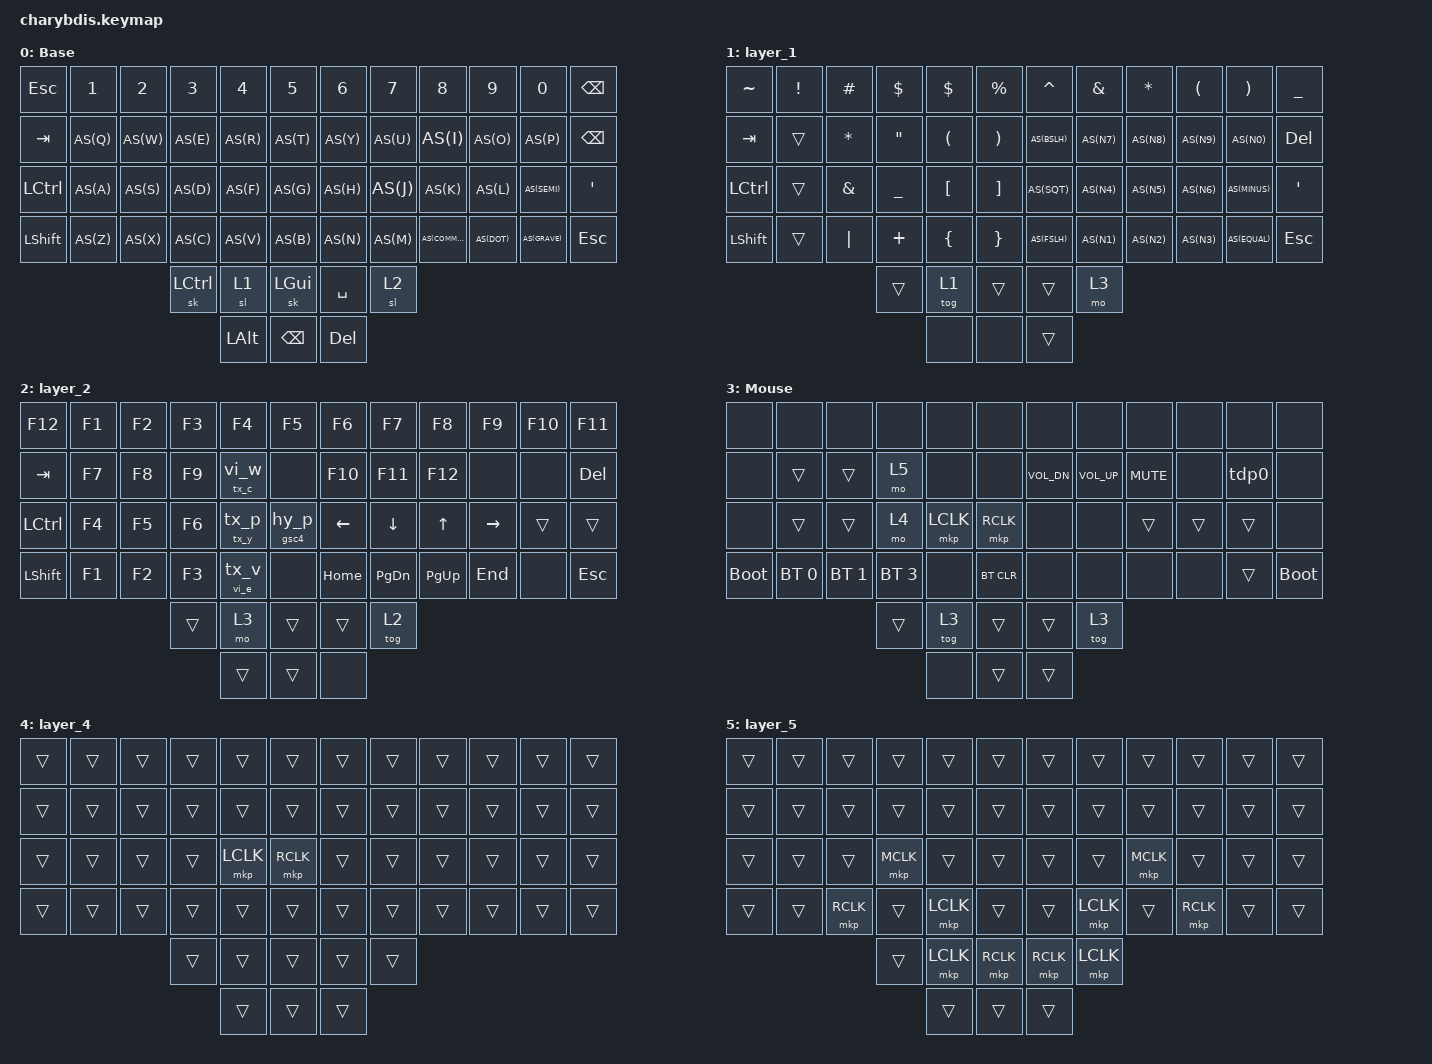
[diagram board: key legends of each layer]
#include <dt-bindings/zmk/mouse.h>
#include <behaviors.dtsi>
#include <dt-bindings/zmk/bt.h>
#include <dt-bindings/zmk/keys.h>

#define AS(keycode) &as LS(keycode) keycode     // Autoshift Macro

&tmv_fine {
    scale_factor = <3>;
};

&tmv_coarse {
    scale_mode = "multiplier";
    scale_factor = <3>;
};

&tsl {
    scale_factor = <8>;
};

/ {
    macros {
        vi_w: vi_w {
            label = "VIM_SAVE";
            compatible = "zmk,behavior-macro";
            #binding-cells = <0>;
            wait-ms = <40>;
            tap-ms = <40>;
            bindings
                = <&macro_tap &kp ESC &kp COLON &kp W &kp ENTER>
                ;
        };
        vi_e: vi_e {
            label = "VIM_RELOADE_BUFFER";
            compatible = "zmk,behavior-macro";
            #binding-cells = <0>;
            wait-ms = <40>;
            tap-ms = <40>;
            bindings
                = <&macro_tap &kp ESC &kp COLON &kp E &kp LS(N1) &kp ENTER>
                ;
        };
        tx_c: tx_c {
            label = "TMUX_COPY_MODE";
            compatible = "zmk,behavior-macro";
            #binding-cells = <0>;
            wait-ms = <40>;
            tap-ms = <40>;
            bindings
                = <&macro_tap &kp LC(B) &kp LBKT>
                ;
        };
        tx_p: tx_p {
            label = "TMUX_PREV_PANE";
            compatible = "zmk,behavior-macro";
            #binding-cells = <0>;
            wait-ms = <40>;
            tap-ms = <40>;
            bindings
                = <&macro_tap &kp LC(B) &kp SEMI>
                ;
        };
        tx_y: tx_y {
            label = "TMUX_PREV_PANE_MAX";
            compatible = "zmk,behavior-macro";
            #binding-cells = <0>;
            wait-ms = <40>;
            tap-ms = <40>;
            bindings
                = <&macro_tap &kp LC(B) &kp Y>
                ;
        };
        tx_v: tx_v {
            label = "TMUX_PREV_PASTE";
            compatible = "zmk,behavior-macro";
            #binding-cells = <0>;
            wait-ms = <40>;
            tap-ms = <40>;
            bindings
                = <&macro_tap &kp LC(B) &kp COLON &kp P &kp A &kp ENTER>
                ;
        };
        hy_p: hy_p {
            label = "HYPER_P";
            compatible = "zmk,behavior-macro";
            #binding-cells = <0>;
            wait-ms = <40>;
            tap-ms = <40>;
            bindings
                = <&macro_tap &kp LG(LA(LS(LC(P))))>
                ;
        };
        gsc4: gsc4 {
            label = "MAC_OS_SCREENSHOT_4";
            compatible = "zmk,behavior-macro";
            #binding-cells = <0>;
            wait-ms = <40>;
            tap-ms = <40>;
            bindings
                = <&macro_tap &kp LG(LS(LC(N4)))>
                ;
        };
        pri0: pri0 {
            label = "PRIVATE_KEY_SEQ_0";
            compatible = "zmk,behavior-macro";
            #binding-cells = <0>;
            wait-ms = <40>;
            tap-ms = <40>;
            bindings
                = <&macro_tap 
                    &kp LS(Z) &kp C &kp T &kp D &kp L &kp A &kp M &kp N &kp U 
                    &kp X &kp D &kp E &kp X &kp D &kp Z &kp O &kp G &kp D &kp M 
                    &kp Z>
                ;
        };
        pri1: pri1 {
            label = "PRIVATE_KEY_SEQ_1";
            compatible = "zmk,behavior-macro";
            #binding-cells = <0>;
            wait-ms = <40>;
            tap-ms = <40>;
            bindings
                = <&macro_tap &kp BSPC>
                , <&macro_wait_time 3500>
                , <&pri0>
                ;
        };
        pri2: pri2 {
            label = "PRIVATE_KEY_SEQ_2";
            compatible = "zmk,behavior-macro";
            #binding-cells = <0>;
            wait-ms = <40>;
            tap-ms = <40>;
            bindings
                = <&macro_tap 
                    &kp C &kp T &kp D &kp L &kp A &kp M &kp N &kp U 
                    &kp Z>
                ;
        };
    };

    behaviors {
        tdl4: tap_dance_toggle_scroll {
            label = "TD_TOGGLE_SCROLL";
            compatible = "zmk,behavior-tap-dance";
            #binding-cells = <0>;
            tapping-term-ms = <175>;
            bindings = <&mo 4>, <&tog 4>;
        };

        tdl5: tap_dance_toggle_sniping {
            label = "TD_TOGGLE_SNIPING";
            compatible = "zmk,behavior-tap-dance";
            #binding-cells = <0>;
            tapping-term-ms = <175>;
            bindings = <&mo 5>, <&tog 5>;
        };

        as: auto_shift {
            label = "AUTO_SHIFT";
            compatible = "zmk,behavior-hold-tap";
            #binding-cells = <2>;
            tapping_term_ms = <155>;
            quick_tap_ms = <154>;
            flavor = "tap-preferred";
            bindings = <&kp>, <&kp>;
        };

        ht_r: hold_tap_at_r {
            label = "HOLD_TAP_AT_R";
            compatible = "zmk,behavior-hold-tap";
            #binding-cells = <2>;
            tapping_term_ms = <155>;
            quick_tap_ms = <120>;
            flavor = "tap-preferred";
            bindings = <&tx_c>, <&vi_w>;
        };

        ht_f: hold_tap_at_f {
            label = "HOLD_TAP_AT_F";
            compatible = "zmk,behavior-hold-tap";
            #binding-cells = <2>;
            tapping_term_ms = <155>;
            quick_tap_ms = <120>;
            flavor = "tap-preferred";
            bindings = <&tx_y>, <&tx_p>;
        };

        ht_v: hold_tap_at_v {
            label = "HOLD_TAP_AT_V";
            compatible = "zmk,behavior-hold-tap";
            #binding-cells = <2>;
            tapping_term_ms = <155>;
            quick_tap_ms = <120>;
            flavor = "tap-preferred";
            bindings = <&vi_e>, <&tx_v>;
        };

        ht_g: hold_tap_at_g {
            label = "HOLD_TAP_AT_G";
            compatible = "zmk,behavior-hold-tap";
            #binding-cells = <2>;
            tapping_term_ms = <155>;
            quick_tap_ms = <120>;
            flavor = "tap-preferred";
            bindings = <&gsc4>, <&hy_p>;
        };

        ht_p: hold_tap_at_p {
            label = "HOLD_TAP_AT_P";
            compatible = "zmk,behavior-hold-tap";
            #binding-cells = <2>;
            tapping_term_ms = <155>;
            quick_tap_ms = <120>;
            flavor = "tap-preferred";
            bindings = <&pri2>, <&pri0>;
        };
        tdp0: tap_dance_private_seq_02 {
            label = "TD_PRIVATE_SEQ_02";
            compatible = "zmk,behavior-tap-dance";
            #binding-cells = <0>;
            tapping-term-ms = <175>;
            bindings = <&none>, <&ht_p 0 0>;
        };
    };

    combos {
        compatible = "zmk,combos";
        // Tmux
        combo_ctrl_b {
            timeout-ms = <25>;
            key-positions = <15 27>; // D, E
            bindings = <&kp LC(B)>;
        };

        // Track ball and mouse clicks
        combo_mo_scroll {
            timeout-ms = <25>;
            key-positions = <14 26>; // S, W
            bindings = <&tdl4>; //<&mo 4>;
        };
        combo_mo_tvm_fine {
            timeout-ms = <25>;
            key-positions = <21 33>; // O, L
            bindings = <&tdl5>; //<&mo 5>;
        };
        combo_left_click {
            timeout-ms = <25>;
            key-positions = <27 28>; // D, F
            bindings = <&mkp LCLK>;
        };
        combo_right_click {
            timeout-ms = <25>;
            key-positions = <28 29>; // F, G
            bindings = <&mkp RCLK>;
        };
        combo_tog_3 {
            timeout-ms = <25>;
            key-positions = <26 38>; // S, X
            bindings = <&tog 3>;
        };


        // Enter/ESC ...
        combo_enter {
            timeout-ms = <25>;
            key-positions = <20 32>; // I, K
            bindings = <&kp ENTER>;
        };
        combo_shift_enter {
            timeout-ms = <25>;
            key-positions = <32 44>; // K, COMMA
            bindings = <&kp LS(ENTER)>;
        };
        combo_tab {
            timeout-ms = <25>;
            key-positions = <31 43>; // J, M
            bindings = <&kp TAB>;
        };
        combo_caps_word {
            timeout-ms = <25>;
            key-positions = <30 42>; // H, N
            bindings = <&caps_word>;
        };
        combo_esc_1 {
            timeout-ms = <25>;
            key-positions = <28 40>; // F, V
            bindings = <&kp ESC>;
        };
        combo_esc_2 {
            timeout-ms = <25>;
            key-positions = <26 33>; // S, L
            bindings = <&kp ESC>;
        };
        combo_bspc {
            timeout-ms = <25>;
            key-positions = <16 28>; // R, F
            bindings = <&kp BSPC>;
        };
        combo_del {
            timeout-ms = <25>;
            key-positions = <17 29>; // T, G
            bindings = <&kp DEL>;
        };

        // Lock screen (MacOS)
        combo_cmd_ctrl_q {
            timeout-ms = <25>;
            key-positions = <28 40 29 41>; // F, V, G, B
            bindings = <&kp LG(LC(Q))>;
        };

        combo_alt_space {
            timeout-ms = <25>;
            key-positions = <31 32>; // J, K
            bindings = <&kp LA(SPACE)>;
        };

        combo_ctrl_alt_space {
            timeout-ms = <25>;
            key-positions = <29 41>; // G, B
            bindings = <&kp LA(LC(SPACE))>;
        };

        combo_ctrl_alt_shift_space {
            timeout-ms = <25>;
            key-positions = <33 45>; // L, .(DOT)
            bindings = <&kp LA(LC(LS(SPACE)))>;
        };

        combo_private_seq_1 {
            timeout-ms = <25>;
            key-positions = <30 31 42 43>; // H, J, N, M
            bindings = <&pri1>;
        };
        
        // Oneshot mods
        combo_shift {
            timeout-ms = <25>;
            key-positions = <26 28>; // S, F
            bindings = <&sk LSHFT>;
        };
        combo_alt {
            timeout-ms = <25>;
            key-positions = <32 33>; // K, L
            bindings = <&sk LALT>;
        };
        combo_gui_shift {
            timeout-ms = <25>;
            key-positions = <43 26>; // M, S
            bindings = <&sk LG(LSHFT)>;
        };
        combo_gui_alt {
            timeout-ms = <40>;
            key-positions = <43 28>; // M, F
            bindings = <&sk LG(LALT)>;
        };
        combo_gui_ctrl {
            timeout-ms = <40>;
            key-positions = <43 39>; // M, C
            bindings = <&sk LG(LCTRL)>;
        };
        combo_gui_shift_alt {
            timeout-ms = <30>;
            key-positions = <43 27>; // M, D
            bindings = <&sk LG(LS(LALT))>;
        };
        combo_gui_shift_ctrl {
            timeout-ms = <40>;
            key-positions = <43 38>; // M, X
            bindings = <&sk LG(LS(LCTRL))>;
        };
        combo_gui_alt_ctrl {
            timeout-ms = <40>;
            key-positions = <43 40>; // M, V
            bindings = <&sk LG(LA(LCTRL))>;
        };
        combo_hyper {
            timeout-ms = <40>;
            key-positions = <43 14>; // M, W
            bindings = <&sk LG(LS(LA(LCTRL)))>;
        };
        combo_meh {
            timeout-ms = <40>;
            key-positions = <40 30>; // V, H
            bindings = <&sk LS(LA(LCTRL))>;
        };
        combo_alt_ctrl {
            timeout-ms = <40>;
            key-positions = <40 31>; // V, J
            bindings = <&sk LA(LCTRL)>;
        };
        combo_alt_shift {
            timeout-ms = <40>;
            key-positions = <40 32>; // V, K
            bindings = <&sk LA(LSHFT)>;
        };
        combo_shift_ctrl {
            timeout-ms = <40>;
            key-positions = <40 33>; // V, L
            bindings = <&sk LC(LSHFT)>;
        };
    };

    keymap {
        compatible = "zmk,keymap";

        Base {
            bindings = <
&kp ESC         &kp N1   &kp N2  &kp N3    &kp N4        &kp N5           &kp N6       &kp N7         &kp N8     &kp N9   &kp N0       &kp BSPC
&kp TAB         AS(Q)    AS(W)   AS(E)     AS(R)         AS(T)            AS(Y)        AS(U)          AS(I)      AS(O)    AS(P)        &kp BACKSPACE
&kp LCTRL       AS(A)    AS(S)   AS(D)     AS(F)         AS(G)            AS(H)        AS(J)          AS(K)      AS(L)    AS(SEMI)     &kp APOS
&kp LEFT_SHIFT  AS(Z)    AS(X)   AS(C)     AS(V)         AS(B)            AS(N)        AS(M)          AS(COMMA)  AS(DOT)  AS(GRAVE)    &kp ESC
                                 &sk LCTRL  &sl 1     &sk LGUI      &kp SPACE  &sl 2
                                           &kp LEFT_ALT  &kp BACKSPACE    &kp DEL
            >;

            trackball-bindings = <&tmv_coarse>;
        };

        layer_1 {
            bindings = <
&kp TILDE         &kp EXCL   &kp HASH    &kp DOLLAR    &kp DOLLAR    &kp PERCENT   &kp CARET  &kp AMPERSAND  &kp ASTERISK      &kp LEFT_PARENTHESIS  &kp RIGHT_PARENTHESIS  &kp UNDERSCORE
&kp TAB           &trans     &kp STAR    &kp DQT       &kp LPAR      &kp RPAR      AS(BSLH)   AS(N7)     AS(N8)     AS(N9)     AS(N0)       &kp DEL
&kp LEFT_CONTROL  &trans     &kp AMPS    &kp UNDER     &kp LBKT      &kp RBKT      AS(SQT)    AS(N4)     AS(N5)     AS(N6)     AS(MINUS)    &kp SQT
&kp LSHFT         &trans     &kp PIPE    &kp PLUS      &kp LBRC      &kp RBRC      AS(FSLH)   AS(N1)     AS(N2)     AS(N3)     AS(EQUAL)    &kp ESC
                                         &trans        &tog 1        &trans        &trans     &mo 3
                                                       &none         &none         &trans
            >;
        };

        layer_2 {
            bindings = <
&kp F12           &kp F1  &kp F2   &kp F3        &kp F4         &kp F5       &kp F6    &kp F7       &kp F8    &kp F9     &kp F10  &kp F11
&kp TAB           &kp F7  &kp F8   &kp F9        &ht_r 0 0      &none        &kp F10   &kp F11      &kp F12   &none      &none    &kp DELETE
&kp LEFT_CONTROL  &kp F4  &kp F5   &kp F6        &ht_f 0 0      &ht_g 0 0    &kp LEFT  &kp DOWN     &kp UP    &kp RIGHT  &trans   &trans
&kp LEFT_SHIFT    &kp F1  &kp F2   &kp F3        &ht_v 0 0      &none        &kp HOME  &kp PG_DN    &kp PG_UP &kp END    &none    &kp ESC
                                   &trans        &mo 3          &trans       &trans    &tog 2
                                                 &trans         &trans       &none
            >;

            
        };

        Mouse {
            bindings = <
&none        &none         &none         &none         &none      &none         &none        &none        &none         &none         &none         &none
&none        &trans        &trans        &mo 5         &none      &none         &kp C_VOL_DN &kp C_VOL_UP &kp C_MUTE    &none         &tdp0         &none
&none        &trans        &trans        &mo 4         &mkp LCLK  &mkp RCLK     &none        &none        &trans        &trans        &trans        &none
&bootloader  &bt BT_SEL 0  &bt BT_SEL 1  &bt BT_SEL 3  &none      &bt BT_CLR    &none        &none        &none         &none         &trans        &bootloader
                                         &trans        &tog 3     &trans        &trans       &tog 3
                                                       &none      &trans        &trans
            >;

            
        };

        layer_4 {
            bindings = <
&trans  &trans  &trans     &trans     &trans     &trans       &trans     &trans     &trans     &trans     &trans  &trans
&trans  &trans  &trans     &trans     &trans     &trans       &trans     &trans     &trans     &trans     &trans  &trans
&trans  &trans  &trans     &trans     &mkp LCLK  &mkp RCLK    &trans     &trans     &trans     &trans     &trans  &trans
&trans  &trans  &trans     &trans     &trans     &trans       &trans     &trans     &trans     &trans     &trans  &trans
                           &trans     &trans     &trans       &trans     &trans
                                      &trans     &trans       &trans
            >;
                
                
                trackball-bindings = <&tsl>;
        };

        layer_5 {
            bindings = <
&trans  &trans  &trans     &trans     &trans     &trans       &trans     &trans     &trans     &trans     &trans  &trans
&trans  &trans  &trans     &trans     &trans     &trans       &trans     &trans     &trans     &trans     &trans  &trans
&trans  &trans  &trans     &mkp MCLK  &trans     &trans       &trans     &trans     &mkp MCLK  &trans     &trans  &trans
&trans  &trans  &mkp RCLK  &trans     &mkp LCLK  &trans       &trans     &mkp LCLK  &trans     &mkp RCLK  &trans  &trans
                           &trans     &mkp LCLK  &mkp RCLK    &mkp RCLK  &mkp LCLK
                                      &trans     &trans       &trans
            >;
                trackball-bindings = <&tmv_fine>;
                
        };
    };

};
